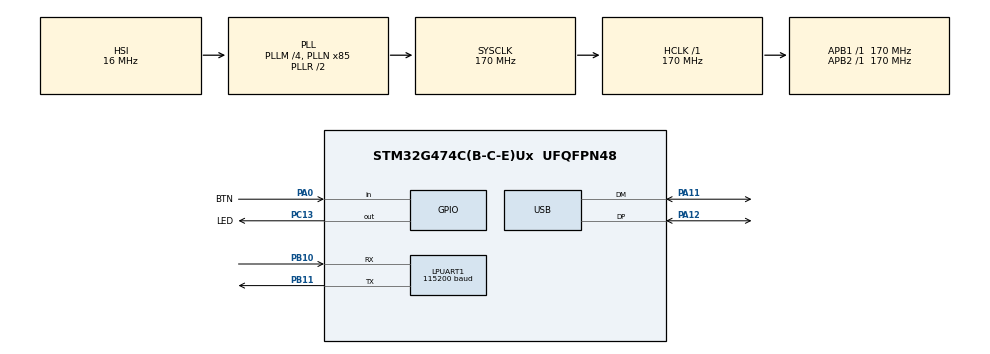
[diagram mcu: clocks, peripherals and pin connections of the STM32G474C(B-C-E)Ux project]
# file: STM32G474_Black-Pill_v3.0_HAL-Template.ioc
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LPUART1.BaudRate=115200
Mcu.Family=STM32G4
Mcu.Name=STM32G474C(B-C-E)Ux
Mcu.Package=UFQFPN48
NVIC.PriorityGroup=NVIC_PRIORITYGROUP_4
NVIC.USB_LP_IRQn=true\:0\:0\:false\:false\:true\:false\:true\:true
PA0.GPIO_Label=BTN
PA0.GPIO_PuPd=GPIO_PULLUP
PA0.Signal=GPIO_Input
PA11.Mode=Device
PA11.Signal=USB_DM
PA12.Mode=Device
PA12.Signal=USB_DP
PA13.Mode=Serial_Wire
PA13.Signal=SYS_JTMS-SWDIO
PA14.Mode=Serial_Wire
PA14.Signal=SYS_JTCK-SWCLK
PB10.Mode=Asynchronous
PB10.Signal=LPUART1_RX
PB11.Mode=Asynchronous
PB11.Signal=LPUART1_TX
PC13.GPIO_Label=LED
PC13.Signal=GPIO_Output
PC14-OSC32_IN.Mode=LSE-External-Oscillator
PC14-OSC32_IN.Signal=RCC_OSC32_IN
PC15-OSC32_OUT.Mode=LSE-External-Oscillator
PC15-OSC32_OUT.Signal=RCC_OSC32_OUT
PF0-OSC_IN.Mode=HSE-External-Oscillator
PF0-OSC_IN.Signal=RCC_OSC_IN
PF1-OSC_OUT.Mode=HSE-External-Oscillator
PF1-OSC_OUT.Signal=RCC_OSC_OUT
ProjectManager.HeapSize=0x200
ProjectManager.StackSize=0x400
ProjectManager.TargetToolchain=STM32CubeIDE
RCC.ADC12Freq_Value=170000000
RCC.ADC345Freq_Value=170000000
RCC.AHBFreq_Value=170000000
RCC.APB1Freq_Value=170000000
RCC.APB1TimFreq_Value=170000000
RCC.APB2Freq_Value=170000000
RCC.APB2TimFreq_Value=170000000
RCC.CK48CLockSelection=RCC_USBCLKSOURCE_HSI48
RCC.CortexFreq_Value=170000000
RCC.EXTERNAL_CLOCK_VALUE=12288000
RCC.HCLKFreq_Value=170000000
RCC.HSE_VALUE=24000000
RCC.HSI48_VALUE=48000000
RCC.HSI_VALUE=16000000
RCC.PLLM=RCC_PLLM_DIV4
RCC.PLLN=85
RCC.SYSCLKFreq_VALUE=170000000
RCC.SYSCLKSource=RCC_SYSCLKSOURCE_PLLCLK
RCC.USBFreq_Value=48000000
RCC.VCOOutputFreq_Value=340000000
USB_DEVICE.CLASS_NAME_FS=CDC
USB_DEVICE.VirtualMode=Cdc
USB_DEVICE.VirtualModeFS=Cdc_FS
VP_SYS_VS_DBSignals.Mode=DisableDeadBatterySignals
VP_USB_DEVICE_VS_USB_DEVICE_CDC_FS.Mode=CDC_FS
board=custom

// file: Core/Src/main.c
/* USER CODE BEGIN Header */
/**
 ******************************************************************************
 * @file           : main.c
 * @brief          : Main program body
 ******************************************************************************
 * @attention
 *
 * Copyright (c) 2023 STMicroelectronics.
 * All rights reserved.
 *
 * This software is licensed under terms that can be found in the LICENSE file
 * in the root directory of this software component.
 * If no LICENSE file comes with this software, it is provided AS-IS.
 *
 ******************************************************************************
 */
/* USER CODE END Header */
#include "main.h"
#include "usart.h"
#include "usb_device.h"
#include "gpio.h"

/* USER CODE BEGIN Includes */
#include "usbd_cdc_if.h"
#include "putchar_getchar_redirect.h"
/* USER CODE END Includes */

void SystemClock_Config(void);

int main(void)
{

	/* MCU Configuration--------------------------------------------------------*/

	/* Reset of all peripherals, Initializes the Flash interface and the Systick. */
	HAL_Init();

	/* USER CODE BEGIN Init */
#ifdef USE_UART_FOR_USB
	/**
	 * @note Disable internal buffering of the input stream to avoid unexpected
	 * behavior with scanf(). Only need with scanf().
	 */
	setvbuf(stdin, NULL, _IONBF, 0);
#endif
	/* USER CODE END Init */

	/* Configure the system clock */
	SystemClock_Config();

	/* Initialize all configured peripherals */
	MX_GPIO_Init();
	MX_USB_Device_Init();
	MX_LPUART1_UART_Init();
	/* USER CODE BEGIN 2 */
	HAL_GPIO_WritePin(LED_GPIO_Port, LED_Pin, GPIO_PIN_SET);
	/* USER CODE END 2 */

	/* Infinite loop */
	/* USER CODE BEGIN WHILE */
	while (1)
	{
		GPIO_PinState state = HAL_GPIO_ReadPin(BTN_GPIO_Port, BTN_Pin);
		HAL_GPIO_WritePin(LED_GPIO_Port, LED_Pin, state);

		if (state == GPIO_PIN_RESET)
		{
			printf("Button is pressed...\n\r");
		}

		HAL_Delay(10);
		/* USER CODE END WHILE */

	}
}

void SystemClock_Config(void)
{
	RCC_OscInitTypeDef RCC_OscInitStruct = { 0 };
	RCC_ClkInitTypeDef RCC_ClkInitStruct = { 0 };

	/** Configure the main internal regulator output voltage
	 */
	HAL_PWREx_ControlVoltageScaling(PWR_REGULATOR_VOLTAGE_SCALE1_BOOST);

	/** Initializes the RCC Oscillators according to the specified parameters
	 * in the RCC_OscInitTypeDef structure.
	 */
	RCC_OscInitStruct.OscillatorType = RCC_OSCILLATORTYPE_HSI
			| RCC_OSCILLATORTYPE_HSI48;
	RCC_OscInitStruct.HSIState = RCC_HSI_ON;
	RCC_OscInitStruct.HSICalibrationValue = RCC_HSICALIBRATION_DEFAULT;
	RCC_OscInitStruct.HSI48State = RCC_HSI48_ON;
	RCC_OscInitStruct.PLL.PLLState = RCC_PLL_ON;
	RCC_OscInitStruct.PLL.PLLSource = RCC_PLLSOURCE_HSI;
	RCC_OscInitStruct.PLL.PLLM = RCC_PLLM_DIV4;
	RCC_OscInitStruct.PLL.PLLN = 85;
	RCC_OscInitStruct.PLL.PLLP = RCC_PLLP_DIV2;
	RCC_OscInitStruct.PLL.PLLQ = RCC_PLLQ_DIV2;
	RCC_OscInitStruct.PLL.PLLR = RCC_PLLR_DIV2;
	if (HAL_RCC_OscConfig(&RCC_OscInitStruct) != HAL_OK)
	{
		Error_Handler();
	}

	/** Initializes the CPU, AHB and APB buses clocks
	 */
	RCC_ClkInitStruct.ClockType = RCC_CLOCKTYPE_HCLK | RCC_CLOCKTYPE_SYSCLK
			| RCC_CLOCKTYPE_PCLK1 | RCC_CLOCKTYPE_PCLK2;
	RCC_ClkInitStruct.SYSCLKSource = RCC_SYSCLKSOURCE_PLLCLK;
	RCC_ClkInitStruct.AHBCLKDivider = RCC_SYSCLK_DIV1;
	RCC_ClkInitStruct.APB1CLKDivider = RCC_HCLK_DIV1;
	RCC_ClkInitStruct.APB2CLKDivider = RCC_HCLK_DIV1;

	if (HAL_RCC_ClockConfig(&RCC_ClkInitStruct, FLASH_LATENCY_4) != HAL_OK)
	{
		Error_Handler();
	}
}

void Error_Handler(void)
{
	/* USER CODE BEGIN Error_Handler_Debug */
	/* User can add his own implementation to report the HAL error return state */
	__disable_irq();
	while (1)
	{
		HAL_GPIO_TogglePin(LED_GPIO_Port, LED_Pin);

		/**
		 * @note NOP is used because HAL_Delay is based on interrupts and does
		 * not work. So in the error state the CPU time does not matter. Led
		 * flashed with approx. 200 Hz.
		 */
		for (unsigned long i = 0; i < 850000; i++)
		{
			asm("NOP");
		}
	}
	/* USER CODE END Error_Handler_Debug */
}
